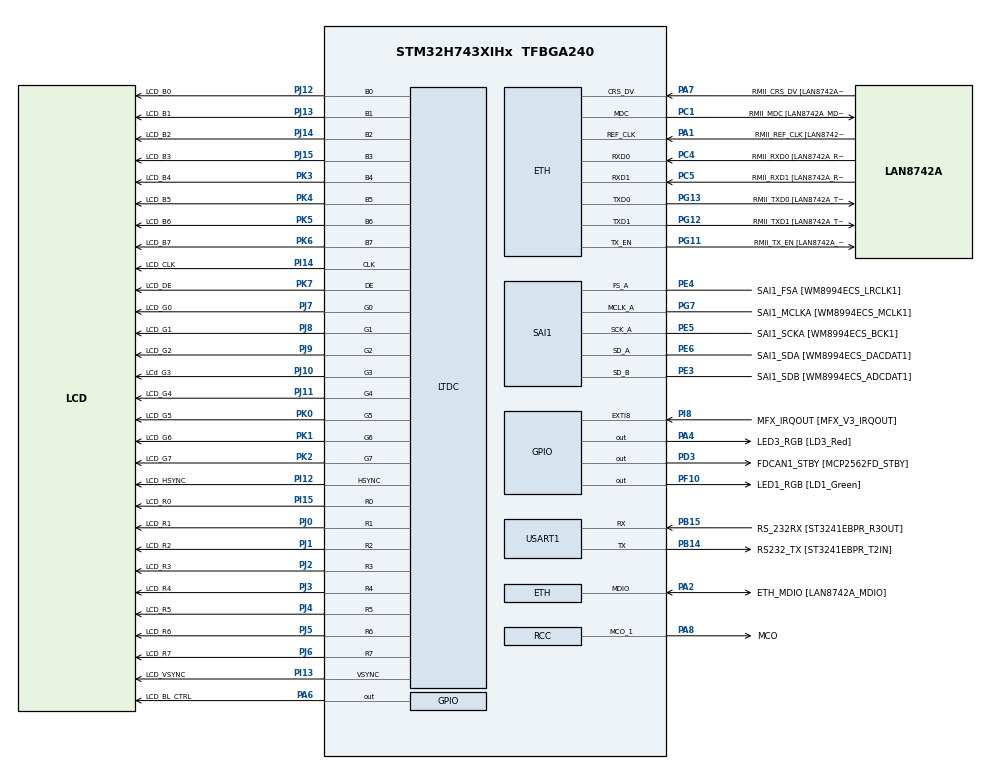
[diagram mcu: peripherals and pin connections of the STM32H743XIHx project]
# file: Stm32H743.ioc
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CORTEX_M7.CPU_DCache=Enabled
ETH.MediaInterface=HAL_ETH_RMII_MODE
FREERTOS.Tasks01=defaultTask,24,512,StartDefaultTask,Default,NULL,Static,defaultTaskBuffer,defaultTaskControlBlock
FREERTOS.configUSE_NEWLIB_REENTRANT=1
LWIP.BSP.number=1
LWIP.IP_ADDRESS=192.168.001.010
LWIP.LWIP_DHCP=0
LWIP.LWIP_TFTP=1
LWIP.NETMASK_ADDRESS=255.255.255.000
LWIP.Version=v2.1.2_Cube
LWIP0.BSP.STBoard=false
LWIP0.BSP.api=BSP_COMPONENT_DRIVER
LWIP0.BSP.component=LAN8742
LWIP0.BSP.instance=LAN8742
LWIP0.BSP.name=Driver_PHY
LWIP0.BSP.semaphore=S_LAN8742
LWIP0.BSP.solution=LAN8742
Mcu.Family=STM32H7
Mcu.Name=STM32H743XIHx
Mcu.Package=TFBGA240
NVIC.PriorityGroup=NVIC_PRIORITYGROUP_4
NVIC.TIM1_UP_IRQn=true\:15\:0\:false\:false\:true\:false\:false\:true\:true
NVIC.TimeBase=TIM1_UP_IRQn
NVIC.TimeBaseIP=TIM1
PA1.GPIO_Label=RMII_REF_CLK [LAN8742A_REFCLK0]
PA1.Mode=RMII
PA1.Signal=ETH_REF_CLK
PA2.GPIO_Label=ETH_MDIO [LAN8742A_MDIO]
PA2.Mode=RMII
PA2.Signal=ETH_MDIO
PA4.GPIO_Label=LED3_RGB [LD3_Red]
PA4.Signal=GPIO_Output
PA6.GPIO_Label=LCD_BL_CTRL
PA6.Signal=GPIO_Output
PA7.GPIO_Label=RMII_CRS_DV [LAN8742A_CRS_DV]
PA7.Mode=RMII
PA7.Signal=ETH_CRS_DV
PA8.GPIO_Label=MCO
PA8.Mode=Clock-out-1
PA8.Signal=RCC_MCO_1
PB14.GPIO_Label=RS232_TX [ST3241EBPR_T2IN]
PB14.Mode=Asynchronous
PB14.Signal=USART1_TX
PB15.GPIO_Label=RS_232RX [ST3241EBPR_R3OUT]
PB15.Mode=Asynchronous
PB15.Signal=USART1_RX
PC1.GPIO_Label=RMII_MDC [LAN8742A_MDC]
PC1.Mode=RMII
PC1.Signal=ETH_MDC
PC14-OSC32_IN\ (OSC32_IN).Mode=LSE-External-Oscillator
PC14-OSC32_IN\ (OSC32_IN).Signal=RCC_OSC32_IN
PC15-OSC32_OUT\ (OSC32_OUT).Mode=LSE-External-Oscillator
PC15-OSC32_OUT\ (OSC32_OUT).Signal=RCC_OSC32_OUT
PC4.GPIO_Label=RMII_RXD0 [LAN8742A_RXD0]
PC4.Mode=RMII
PC4.Signal=ETH_RXD0
PC5.GPIO_Label=RMII_RXD1 [LAN8742A_RXD1]
PC5.Mode=RMII
PC5.Signal=ETH_RXD1
PD3.GPIO_Label=FDCAN1_STBY [MCP2562FD_STBY]
PD3.Signal=GPIO_Output
PE2.GPIO_Label=PDM1_CLK
PE2.Signal=SAI4_CK1
PE3.GPIO_Label=SAI1_SDB [WM8994ECS_ADCDAT1]
PE3.Mode=SAI_B_SyncSlave
PE3.Signal=SAI1_SD_B
PE4.GPIO_Label=SAI1_FSA [WM8994ECS_LRCLK1]
PE4.Mode=SAI_A_MasterWithClock
PE4.Signal=SAI1_FS_A
PE5.GPIO_Label=SAI1_SCKA [WM8994ECS_BCK1]
PE5.Mode=SAI_A_MasterWithClock
PE5.Signal=SAI1_SCK_A
PE6.GPIO_Label=SAI1_SDA [WM8994ECS_DACDAT1]
PE6.Mode=SAI_A_MasterWithClock
PE6.Signal=SAI1_SD_A
PF10.GPIO_Label=LED1_RGB [LD1_Green]
PF10.Signal=GPIO_Output
PG11.GPIO_Label=RMII_TX_EN [LAN8742A_TXEN]
PG11.Mode=RMII
PG11.Signal=ETH_TX_EN
PG12.GPIO_Label=RMII_TXD1 [LAN8742A_TXD1]
PG12.Mode=RMII
PG12.Signal=ETH_TXD1
PG13.GPIO_Label=RMII_TXD0 [LAN8742A_TXD0]
PG13.Mode=RMII
PG13.Signal=ETH_TXD0
PG7.GPIO_Label=SAI1_MCLKA [WM8994ECS_MCLK1]
PG7.Mode=SAI_A_MasterWithClock
PG7.Signal=SAI1_MCLK_A
PH0-OSC_IN\ (PH0).Mode=HSE-External-Oscillator
PH0-OSC_IN\ (PH0).Signal=RCC_OSC_IN
PH1-OSC_OUT\ (PH1).Mode=HSE-External-Oscillator
PH1-OSC_OUT\ (PH1).Signal=RCC_OSC_OUT
PI12.GPIO_Label=LCD_HSYNC
PI12.Mode=RGB888
PI12.Signal=LTDC_HSYNC
PI13.GPIO_Label=LCD_VSYNC
PI13.Mode=RGB888
PI13.Signal=LTDC_VSYNC
PI14.GPIO_Label=LCD_CLK
PI14.Mode=RGB888
PI14.Signal=LTDC_CLK
PI15.GPIO_Label=LCD_R0
PI15.Mode=RGB888
PI15.Signal=LTDC_R0
PI8.GPIO_Label=MFX_IRQOUT [MFX_V3_IRQOUT]
PI8.Signal=GPXTI8
PJ0.GPIO_Label=LCD_R1
PJ0.Mode=RGB888
PJ0.Signal=LTDC_R1
PJ1.GPIO_Label=LCD_R2
PJ1.Mode=RGB888
PJ1.Signal=LTDC_R2
PJ10.GPIO_Label=LCd_G3
PJ10.Mode=RGB888
PJ10.Signal=LTDC_G3
PJ11.GPIO_Label=LCD_G4
PJ11.Mode=RGB888
PJ11.Signal=LTDC_G4
PJ12.GPIO_Label=LCD_B0
PJ12.Mode=RGB888
PJ12.Signal=LTDC_B0
PJ13.GPIO_Label=LCD_B1
PJ13.Mode=RGB888
PJ13.Signal=LTDC_B1
PJ14.GPIO_Label=LCD_B2
PJ14.Mode=RGB888
PJ14.Signal=LTDC_B2
PJ15.GPIO_Label=LCD_B3
PJ15.Mode=RGB888
PJ15.Signal=LTDC_B3
PJ2.GPIO_Label=LCD_R3
PJ2.Mode=RGB888
PJ2.Signal=LTDC_R3
PJ3.GPIO_Label=LCD_R4
PJ3.Mode=RGB888
PJ3.Signal=LTDC_R4
PJ4.GPIO_Label=LCD_R5
PJ4.Mode=RGB888
PJ4.Signal=LTDC_R5
PJ5.GPIO_Label=LCD_R6
PJ5.Mode=RGB888
PJ5.Signal=LTDC_R6
PJ6.GPIO_Label=LCD_R7
PJ6.Mode=RGB888
PJ6.Signal=LTDC_R7
PJ7.GPIO_Label=LCD_G0
PJ7.Mode=RGB888
PJ7.Signal=LTDC_G0
PJ8.GPIO_Label=LCD_G1
PJ8.Mode=RGB888
PJ8.Signal=LTDC_G1
PJ9.GPIO_Label=LCD_G2
PJ9.Mode=RGB888
PJ9.Signal=LTDC_G2
PK0.GPIO_Label=LCD_G5
PK0.Mode=RGB888
PK0.Signal=LTDC_G5
PK1.GPIO_Label=LCD_G6
PK1.Mode=RGB888
PK1.Signal=LTDC_G6
PK2.GPIO_Label=LCD_G7
PK2.Mode=RGB888
PK2.Signal=LTDC_G7
PK3.GPIO_Label=LCD_B4
PK3.Mode=RGB888
PK3.Signal=LTDC_B4
PK4.GPIO_Label=LCD_B5
PK4.Mode=RGB888
PK4.Signal=LTDC_B5
PK5.GPIO_Label=LCD_B6
PK5.Mode=RGB888
PK5.Signal=LTDC_B6
PK6.GPIO_Label=LCD_B7
PK6.Mode=RGB888
PK6.Signal=LTDC_B7
PK7.GPIO_Label=LCD_DE
PK7.Mode=RGB888
PK7.Signal=LTDC_DE
ProjectManager.HeapSize=0x200
ProjectManager.StackSize=0x400
ProjectManager.TargetToolchain=STM32CubeIDE
RCC.ADCFreq_Value=75000000
RCC.APB1Freq_Value=75000000
RCC.APB2Freq_Value=18750000
RCC.APB3Freq_Value=75000000
RCC.APB4Freq_Value=75000000
RCC.CortexFreq_Value=75000000
RCC.D2PPRE2=RCC_APB2_DIV4
RCC.DIVM1=4
RCC.DIVM2=4
RCC.DIVM3=1
RCC.DIVN1=9
RCC.DIVN2=9
RCC.DIVN3=4
RCC.DIVQ1=1
RCC.HCLKFreq_Value=75000000
RCC.PLL2FRACN=3072
RCC.PLL3FRACN=0
RCC.PLLFRACN=3072
RCC.PWR_Regulator_Voltage_Scale=PWR_REGULATOR_VOLTAGE_SCALE1
RCC.SYSCLKFreq_VALUE=75000000
RCC.SYSCLKSource=RCC_SYSCLKSOURCE_PLLCLK
RCC.USBCLockSelection=RCC_USBCLKSOURCE_HSI48
RCC.USBFreq_Value=48000000
SAI1.ErrorAudioFreq-SAI_A_MasterWithClock=52.58 %
SAI1.Instance-SAI_A_MasterWithClock=SAI$Index_Block_A
SAI1.Instance-SAI_B_SyncSlave=SAI$Index_Block_B
SAI1.MClockEnable-SAI_A_MasterWithClock=SAI_MASTERCLOCK_ENABLE
SAI1.RealAudioFreq-SAI_A_MasterWithClock=292.968 KHz
SAI1.VirtualMode-SAI_A_MasterWithClock=VM_MASTER
SAI1.VirtualMode-SAI_B_SyncSlave=VM_SLAVE
USART1.VirtualMode-Asynchronous=VM_ASYNC
VP_FREERTOS_VS_CMSIS_V2.Mode=CMSIS_V2
VP_LWIP_VS_Enabled.Mode=Enabled
VP_MBEDTLS_VS_MBEDTLS.Mode=Enabled
VP_SYS_VS_tim1.Mode=TIM1
board=STM32H743I-EVAL2

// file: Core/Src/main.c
/* USER CODE BEGIN Header */
/**
  ******************************************************************************
  * @file           : main.c
  * @brief          : Main program body
  ******************************************************************************
  * @attention
  *
  * Copyright (c) 2023 STMicroelectronics.
  * All rights reserved.
  *
  * This software is licensed under terms that can be found in the LICENSE file
  * in the root directory of this software component.
  * If no LICENSE file comes with this software, it is provided AS-IS.
  *
  ******************************************************************************
  */
/* USER CODE END Header */
#include "main.h"
#include "cmsis_os.h"
#include "ltdc.h"
#include "mbedtls.h"
#include "sai.h"
#include "usart.h"
#include "gpio.h"

/* USER CODE BEGIN Includes */
#include "../../rtg/rtg_main.h"
/* USER CODE END Includes */

void SystemClock_Config(void);
void MX_FREERTOS_Init(void);

/* USER CODE BEGIN 0 */
#include <sys/time.h>

int _gettimeofday(struct timeval *tv, void *tzvp) {
    uint32_t t = HAL_GetTick();  		// millis
    tv->tv_sec = t / 1000;  			// convert to seconds
    tv->tv_usec = (t % 1000) * 1000;	// get remaining microseconds
    return 0;
}
/* USER CODE END 0 */

int main(void)
{

  /* Enable D-Cache---------------------------------------------------------*/
  SCB_EnableDCache();

  /* MCU Configuration--------------------------------------------------------*/

  /* Reset of all peripherals, Initializes the Flash interface and the Systick. */
  HAL_Init();

  /* Configure the system clock */
  SystemClock_Config();

  /* Initialize all configured peripherals */
  MX_GPIO_Init();
  MX_LTDC_Init();
  MX_SAI1_Init();
  MX_USART1_UART_Init();
  MX_MBEDTLS_Init();
  /* Call PreOsInit function */
  MX_MBEDTLS_Init();

  /* Init scheduler */
  osKernelInitialize();  /* Call init function for freertos objects (in freertos.c) */
  MX_FREERTOS_Init();

  /* Start scheduler */
  osKernelStart();

  /* We should never get here as control is now taken by the scheduler */
  /* Infinite loop */
  while (1)
  {

  }
}

void SystemClock_Config(void)
{
  RCC_OscInitTypeDef RCC_OscInitStruct = {0};
  RCC_ClkInitTypeDef RCC_ClkInitStruct = {0};

  /** Supply configuration update enable
  */
  HAL_PWREx_ConfigSupply(PWR_LDO_SUPPLY);

  /** Configure the main internal regulator output voltage
  */
  __HAL_PWR_VOLTAGESCALING_CONFIG(PWR_REGULATOR_VOLTAGE_SCALE1);

  while(!__HAL_PWR_GET_FLAG(PWR_FLAG_VOSRDY)) {}

  /** Initializes the RCC Oscillators according to the specified parameters
  * in the RCC_OscInitTypeDef structure.
  */
  RCC_OscInitStruct.OscillatorType = RCC_OSCILLATORTYPE_HSI;
  RCC_OscInitStruct.HSIState = RCC_HSI_DIV1;
  RCC_OscInitStruct.HSICalibrationValue = RCC_HSICALIBRATION_DEFAULT;
  RCC_OscInitStruct.PLL.PLLState = RCC_PLL_ON;
  RCC_OscInitStruct.PLL.PLLSource = RCC_PLLSOURCE_HSI;
  RCC_OscInitStruct.PLL.PLLM = 4;
  RCC_OscInitStruct.PLL.PLLN = 9;
  RCC_OscInitStruct.PLL.PLLP = 2;
  RCC_OscInitStruct.PLL.PLLQ = 1;
  RCC_OscInitStruct.PLL.PLLR = 2;
  RCC_OscInitStruct.PLL.PLLRGE = RCC_PLL1VCIRANGE_3;
  RCC_OscInitStruct.PLL.PLLVCOSEL = RCC_PLL1VCOMEDIUM;
  RCC_OscInitStruct.PLL.PLLFRACN = 3072;
  if (HAL_RCC_OscConfig(&RCC_OscInitStruct) != HAL_OK)
  {
    Error_Handler();
  }

  /** Initializes the CPU, AHB and APB buses clocks
  */
  RCC_ClkInitStruct.ClockType = RCC_CLOCKTYPE_HCLK|RCC_CLOCKTYPE_SYSCLK
                              |RCC_CLOCKTYPE_PCLK1|RCC_CLOCKTYPE_PCLK2
                              |RCC_CLOCKTYPE_D3PCLK1|RCC_CLOCKTYPE_D1PCLK1;
  RCC_ClkInitStruct.SYSCLKSource = RCC_SYSCLKSOURCE_PLLCLK;
  RCC_ClkInitStruct.SYSCLKDivider = RCC_SYSCLK_DIV1;
  RCC_ClkInitStruct.AHBCLKDivider = RCC_HCLK_DIV1;
  RCC_ClkInitStruct.APB3CLKDivider = RCC_APB3_DIV1;
  RCC_ClkInitStruct.APB1CLKDivider = RCC_APB1_DIV1;
  RCC_ClkInitStruct.APB2CLKDivider = RCC_APB2_DIV4;
  RCC_ClkInitStruct.APB4CLKDivider = RCC_APB4_DIV1;

  if (HAL_RCC_ClockConfig(&RCC_ClkInitStruct, FLASH_LATENCY_1) != HAL_OK)
  {
    Error_Handler();
  }
  HAL_RCC_MCOConfig(RCC_MCO1, RCC_MCO1SOURCE_HSI, RCC_MCODIV_1);
}

void HAL_TIM_PeriodElapsedCallback(TIM_HandleTypeDef *htim)
{
  if (htim->Instance == TIM1) {
    HAL_IncTick();
  }
}

void Error_Handler(void)
{
  __disable_irq();
  while (1)
  {
  }
}

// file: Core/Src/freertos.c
/* USER CODE BEGIN Header */
/**
  ******************************************************************************
  * File Name          : freertos.c
  * Description        : Code for freertos applications
  ******************************************************************************
  * @attention
  *
  * Copyright (c) 2023 STMicroelectronics.
  * All rights reserved.
  *
  * This software is licensed under terms that can be found in the LICENSE file
  * in the root directory of this software component.
  * If no LICENSE file comes with this software, it is provided AS-IS.
  *
  ******************************************************************************
  */
/* USER CODE END Header */

#include "FreeRTOS.h"
#include "task.h"
#include "main.h"
#include "cmsis_os.h"

/* USER CODE BEGIN Includes */
#include <stdio.h>
/* USER CODE END Includes */

typedef StaticTask_t osStaticThreadDef_t;

/* Definitions for defaultTask */
osThreadId_t defaultTaskHandle;
uint32_t defaultTaskBuffer[ 512 ];
osStaticThreadDef_t defaultTaskControlBlock;
const osThreadAttr_t defaultTask_attributes = {
  .name = "defaultTask",
  .cb_mem = &defaultTaskControlBlock,
  .cb_size = sizeof(defaultTaskControlBlock),
  .stack_mem = &defaultTaskBuffer[0],
  .stack_size = sizeof(defaultTaskBuffer),
  .priority = (osPriority_t) osPriorityNormal,
};

void StartDefaultTask(void *argument);

extern void MX_LWIP_Init(void);
void MX_FREERTOS_Init(void); /* (MISRA C 2004 rule 8.1) */

void MX_FREERTOS_Init(void) {

  /* Create the thread(s) */
  /* creation of defaultTask */
  defaultTaskHandle = osThreadNew(StartDefaultTask, NULL, &defaultTask_attributes);

}

/* USER CODE BEGIN Header_StartDefaultTask */
/**
  * @brief  Function implementing the defaultTask thread.
  * @param  argument: Not used
  * @retval None
  */
#include "../../rtg/rtg_main.h"

__weak
/* USER CODE END Header_StartDefaultTask */
void StartDefaultTask(void *argument)
{
  /* USER CODE BEGIN StartDefaultTask */
  /* Infinite loop */
//	rtg_main();
  /* USER CODE END StartDefaultTask */
}
